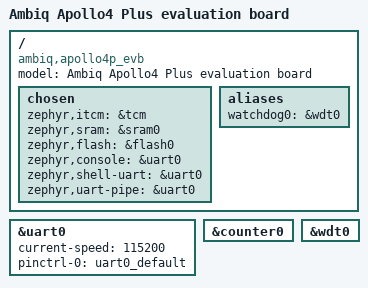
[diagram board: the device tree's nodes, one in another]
/dts-v1/;
#include <ambiq/ambiq_apollo4p.dtsi>

#include "apollo4p_evb-pinctrl.dtsi"

/ {
	model = "Ambiq Apollo4 Plus evaluation board";
	compatible = "ambiq,apollo4p_evb";
	chosen {
		zephyr,itcm = &tcm;
		zephyr,sram = &sram0;
		zephyr,flash = &flash0;
		zephyr,console = &uart0;
		zephyr,shell-uart = &uart0;
		zephyr,uart-pipe = &uart0;
	};
	aliases {
		watchdog0 = &wdt0;
	};
};

&uart0 {
	current-speed = <115200>;
	pinctrl-0 = <&uart0_default>;
	pinctrl-names = "default";
	status = "okay";
};

&counter0 {
	status = "okay";
};

&wdt0 {
	status = "okay";
};
